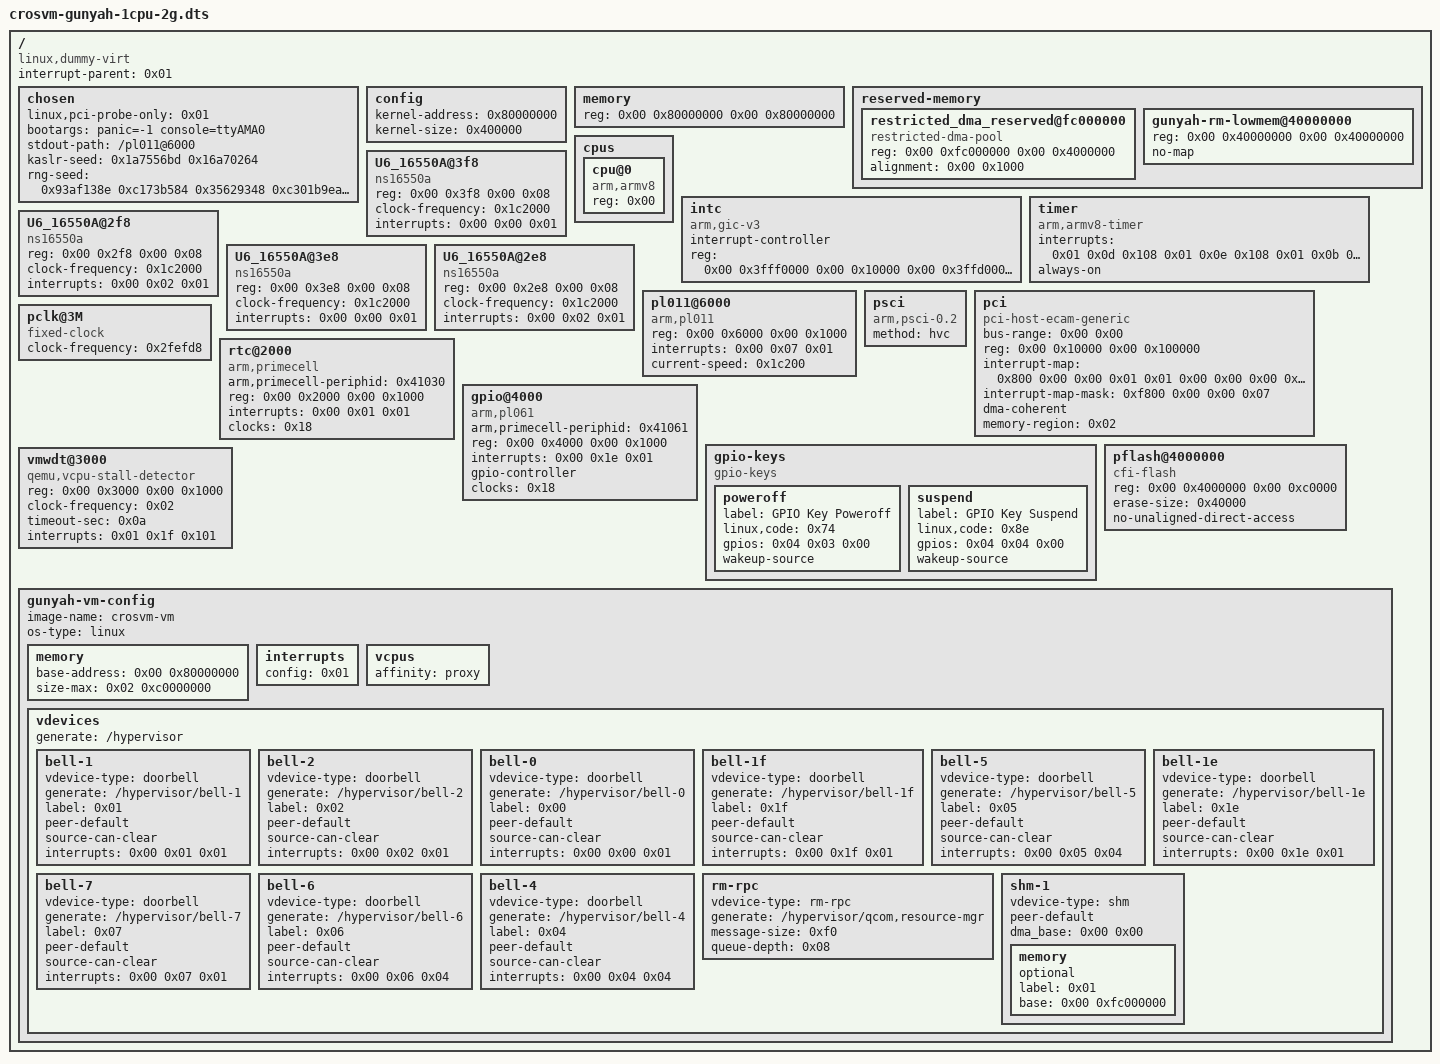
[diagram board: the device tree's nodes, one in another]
/dts-v1/;

/ {
	interrupt-parent = <0x01>;
	compatible = "linux,dummy-virt";
	#address-cells = <0x02>;
	#size-cells = <0x02>;

	chosen {
		linux,pci-probe-only = <0x01>;
		bootargs = "panic=-1 console=ttyAMA0";
		stdout-path = "/pl011@6000";
		kaslr-seed = <0x1a7556bd 0x16a70264>;
		rng-seed = <0x93af138e 0xc173b584 0x35629348 0xc301b9ea 0x49d14d3 0x5a66ee7a 0xd7247f15 0x59b0e0cb 0x51373608 0x4a5d956a 0x6f3ca55f 0xeb3e52e6 0x51bd5b9a 0x60bd1e7c 0x48fb05ba 0xd9d2e906 0x45445415 0x78542f83 0x2adaed4a 0x9d791327 0x6bffac33 0x97c72675 0x6fe7fe21 0x61bdc66e 0xcb38a74f 0x9ec81383 0xc5a93505 0x2bd71e80 0x9a446d03 0x53a2337c 0x4e190221 0x8dad08c8 0xc5344d8f 0x8f0cebfc 0x4578ce6a 0x8351ba4e 0xf521262a 0x85452d8d 0xcec2ca56 0x879b6bca 0x757fe1ea 0xba9dbdfa 0x6eb3e479 0xb14da6f3 0xb74cc69e 0x94c83aaa 0x6c32c6d1 0xb96052eb 0x52346bbd 0x58b328a 0xf5515815 0x663a5dd9 0x5504374a 0xb3f4e2ed 0xfc6cd86 0xa1771dc3 0x162e951e 0xb1b4d651 0x1039cf09 0x9b2fcc02 0xc2374cc6 0x4a9730a5 0x55e54df8 0x2adb13f7>;
	};

	config {
		kernel-address = <0x80000000>;
		kernel-size = <0x400000>;
	};

	memory {
		device_type = "memory";
		reg = <0x00 0x80000000 0x00 0x80000000>;
	};

	reserved-memory {
		#address-cells = <0x02>;
		#size-cells = <0x02>;
		ranges;

		restricted_dma_reserved@fc000000 {
			reg = <0x00 0xfc000000 0x00 0x4000000>;
			phandle = <0x02>;
			compatible = "restricted-dma-pool";
			alignment = <0x00 0x1000>;
		};

		gunyah-rm-lowmem@40000000 {
			reg = <0x00 0x40000000 0x00 0x40000000>;
			no-map;
		};
	};

	cpus {
		#address-cells = <0x01>;
		#size-cells = <0x00>;

		cpu@0 {
			device_type = "cpu";
			compatible = "arm,armv8";
			reg = <0x00>;
			phandle = <0x100>;
		};
	};

	intc: intc {
		compatible = "arm,gic-v3";
		#interrupt-cells = <0x03>;
		interrupt-controller;
		reg = <0x00 0x3fff0000 0x00 0x10000 0x00 0x3ffd0000 0x00 0x20000>;
		phandle = <0x01>;
		#address-cells = <0x02>;
		#size-cells = <0x02>;
	};

	__symbols__ {
		intc = "/intc";
	};

	timer {
		compatible = "arm,armv8-timer";
		interrupts = <0x01 0x0d 0x108 0x01 0x0e 0x108 0x01 0x0b 0x108 0x01 0x0a 0x108>;
		always-on;
	};

	U6_16550A@3f8 {
		compatible = "ns16550a";
		reg = <0x00 0x3f8 0x00 0x08>;
		clock-frequency = <0x1c2000>;
		interrupts = <0x00 0x00 0x01>;
	};

	U6_16550A@2f8 {
		compatible = "ns16550a";
		reg = <0x00 0x2f8 0x00 0x08>;
		clock-frequency = <0x1c2000>;
		interrupts = <0x00 0x02 0x01>;
	};

	U6_16550A@3e8 {
		compatible = "ns16550a";
		reg = <0x00 0x3e8 0x00 0x08>;
		clock-frequency = <0x1c2000>;
		interrupts = <0x00 0x00 0x01>;
	};

	U6_16550A@2e8 {
		compatible = "ns16550a";
		reg = <0x00 0x2e8 0x00 0x08>;
		clock-frequency = <0x1c2000>;
		interrupts = <0x00 0x02 0x01>;
	};

	pl011@6000 {
		compatible = "arm,pl011", "arm,sbsa-uart";
		reg = <0x00 0x6000 0x00 0x1000>;
		interrupts = <0x00 0x07 0x01>;
		current-speed = <0x1c200>;
	};

	psci {
		compatible = "arm,psci-0.2";
		method = "hvc";
	};

	pci {
		compatible = "pci-host-ecam-generic";
		device_type = "pci";
		ranges = <0x2000000 0x00 0x2000000 0x00 0x2000000 0x00 0x2000000 0x43000000 0x01 0x800000 0x01 0x800000 0x02 0x1f800000>;
		bus-range = <0x00 0x00>;
		#address-cells = <0x03>;
		#size-cells = <0x02>;
		reg = <0x00 0x10000 0x00 0x100000>;
		#interrupt-cells = <0x01>;
		interrupt-map = <0x800 0x00 0x00 0x01 0x01 0x00 0x00 0x00 0x04 0x04 0x1000 0x00 0x00 0x01 0x01 0x00 0x00 0x00 0x05 0x04 0x1800 0x00 0x00 0x01 0x01 0x00 0x00 0x00 0x06 0x04>;
		interrupt-map-mask = <0xf800 0x00 0x00 0x07>;
		dma-coherent;
		memory-region = <0x02>;
	};

	pclk@3M {
		#clock-cells = <0x00>;
		compatible = "fixed-clock";
		clock-frequency = <0x2fefd8>;
		phandle = <0x18>;
	};

	rtc@2000 {
		compatible = "arm,primecell";
		arm,primecell-periphid = <0x41030>;
		reg = <0x00 0x2000 0x00 0x1000>;
		interrupts = <0x00 0x01 0x01>;
		clocks = <0x18>;
		clock-names = "apb_pclk";
	};

	gpio@4000 {
		compatible = "arm,pl061", "arm,primecell";
		arm,primecell-periphid = <0x41061>;
		reg = <0x00 0x4000 0x00 0x1000>;
		interrupts = <0x00 0x1e 0x01>;
		gpio-controller;
		#gpio-cells = <0x02>;
		clocks = <0x18>;
		clock-names = "apb_pclk";
		phandle = <0x04>;
	};

	gpio-keys {
		compatible = "gpio-keys";

		poweroff {
			label = "GPIO Key Poweroff";
			linux,code = <0x74>;
			gpios = <0x04 0x03 0x00>;
			wakeup-source;
		};

		suspend {
			label = "GPIO Key Suspend";
			linux,code = <0x8e>;
			gpios = <0x04 0x04 0x00>;
			wakeup-source;
		};
	};

	pflash@4000000 {
		compatible = "cfi-flash";
		reg = <0x00 0x4000000 0x00 0xc0000>;
		erase-size = <0x40000>;
		no-unaligned-direct-access;
		status = "okay";
	};

	vmwdt@3000 {
		compatible = "qemu,vcpu-stall-detector";
		reg = <0x00 0x3000 0x00 0x1000>;
		clock-frequency = <0x02>;
		timeout-sec = <0x0a>;
		interrupts = <0x01 0x1f 0x101>;
	};

	gunyah-vm-config {
		image-name = "crosvm-vm";
		os-type = "linux";

		memory {
			#address-cells = <0x02>;
			#size-cells = <0x02>;
			base-address = <0x00 0x80000000>;
			size-max = <0x02 0xc0000000>;
		};

		interrupts {
			config = <0x01>;
		};

		vcpus {
			affinity = "proxy";
		};

		vdevices {
			generate = "/hypervisor";

			bell-1 {
				vdevice-type = "doorbell";
				generate = "/hypervisor/bell-1";
				label = <0x01>;
				peer-default;
				source-can-clear;
				interrupts = <0x00 0x01 0x01>;
			};

			bell-2 {
				vdevice-type = "doorbell";
				generate = "/hypervisor/bell-2";
				label = <0x02>;
				peer-default;
				source-can-clear;
				interrupts = <0x00 0x02 0x01>;
			};

			bell-0 {
				vdevice-type = "doorbell";
				generate = "/hypervisor/bell-0";
				label = <0x00>;
				peer-default;
				source-can-clear;
				interrupts = <0x00 0x00 0x01>;
			};

			bell-1f {
				vdevice-type = "doorbell";
				generate = "/hypervisor/bell-1f";
				label = <0x1f>;
				peer-default;
				source-can-clear;
				interrupts = <0x00 0x1f 0x01>;
			};

			bell-5 {
				vdevice-type = "doorbell";
				generate = "/hypervisor/bell-5";
				label = <0x05>;
				peer-default;
				source-can-clear;
				interrupts = <0x00 0x05 0x04>;
			};

			bell-1e {
				vdevice-type = "doorbell";
				generate = "/hypervisor/bell-1e";
				label = <0x1e>;
				peer-default;
				source-can-clear;
				interrupts = <0x00 0x1e 0x01>;
			};

			bell-7 {
				vdevice-type = "doorbell";
				generate = "/hypervisor/bell-7";
				label = <0x07>;
				peer-default;
				source-can-clear;
				interrupts = <0x00 0x07 0x01>;
			};

			bell-6 {
				vdevice-type = "doorbell";
				generate = "/hypervisor/bell-6";
				label = <0x06>;
				peer-default;
				source-can-clear;
				interrupts = <0x00 0x06 0x04>;
			};

			bell-4 {
				vdevice-type = "doorbell";
				generate = "/hypervisor/bell-4";
				label = <0x04>;
				peer-default;
				source-can-clear;
				interrupts = <0x00 0x04 0x04>;
			};

			rm-rpc {
				vdevice-type = "rm-rpc";
				generate = "/hypervisor/qcom,resource-mgr";
				message-size = <0xf0>;
				queue-depth = <0x08>;
			};

			shm-1 {
				vdevice-type = "shm";
				peer-default;
				dma_base = <0x00 0x00>;

				memory {
					optional;
					label = <0x01>;
					#address-cells = <0x02>;
					base = <0x00 0xfc000000>;
				};
			};
		};
	};
};
